# STM32H750 register map
File version: 2.7
CPU: CM7 r0p1, little endian, MPU, FPU, 4 interrupt priority bits
Registers are 32-bit, read-write, reset 0x0 unless marked. A register's access mark holds for its fields unless they carry their own. Offsets are from the block's base; [hi:lo] are bit positions; {n}, {i} and the like mark numbered series.

## COMP1
Base 0x58003800
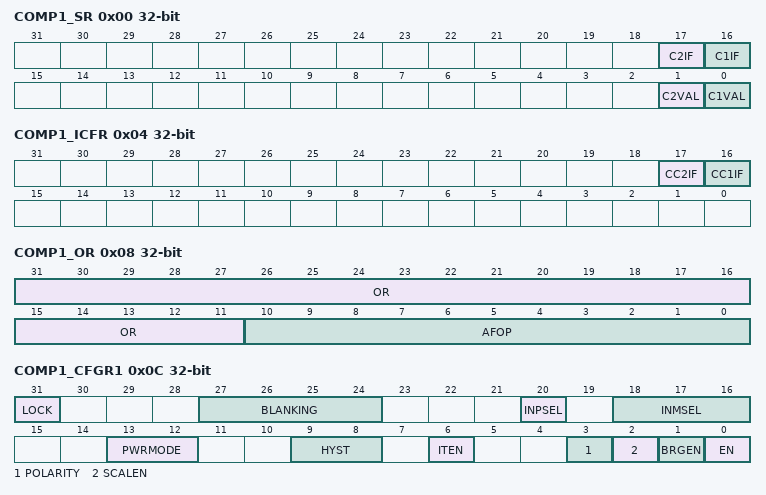
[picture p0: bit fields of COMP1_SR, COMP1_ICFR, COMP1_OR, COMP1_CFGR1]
0x00 COMP1_SR ro — Comparator status register
  [17] C2IF — COMP channel 2 Interrupt Flag
  [16] C1IF — COMP channel 1 Interrupt Flag
  [1] C2VAL — COMP channel 2 output status bit
  [0] C1VAL — COMP channel 1 output status bit
0x04 COMP1_ICFR wo — Comparator interrupt clear flag register
  [17] CC2IF — Clear COMP channel 2 Interrupt Flag
  [16] CC1IF — Clear COMP channel 1 Interrupt Flag
0x08 COMP1_OR — Comparator option register
  [31:11] OR — Option Register
  [10:0] AFOP — Selection of source for alternate function of output ports
0x0C COMP1_CFGR1 — Comparator configuration register 1
  [31] LOCK — Lock bit
  [27:24] BLANKING — COMP channel 1 blanking source selection bits
  [20] INPSEL — COMP channel 1 non-inverting input selection bit
  [18:16] INMSEL — COMP channel 1 inverting input selection field
  [13:12] PWRMODE — Power Mode of the COMP channel 1
  [9:8] HYST — COMP channel 1 hysteresis selection bits
  [6] ITEN — COMP channel 1 interrupt enable
  [3] POLARITY — COMP channel 1 polarity selection bit
  [2] SCALEN — Voltage scaler enable bit
  [1] BRGEN — Scaler bridge enable
  [0] EN — COMP channel 1 enable bit
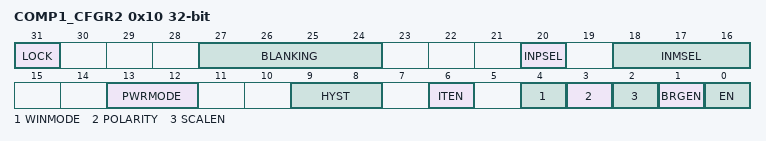
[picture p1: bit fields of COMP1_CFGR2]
0x10 COMP1_CFGR2 — Comparator configuration register 2
  [31] LOCK — Lock bit
  [27:24] BLANKING — COMP channel 1 blanking source selection bits
  [20] INPSEL — COMP channel 1 non-inverting input selection bit
  [18:16] INMSEL — COMP channel 1 inverting input selection field
  [13:12] PWRMODE — Power Mode of the COMP channel 1
  [9:8] HYST — COMP channel 1 hysteresis selection bits
  [6] ITEN — COMP channel 1 interrupt enable
  [4] WINMODE — Window comparator mode selection bit
  [3] POLARITY — COMP channel 1 polarity selection bit
  [2] SCALEN — Voltage scaler enable bit
  [1] BRGEN — Scaler bridge enable
  [0] EN — COMP channel 1 enable bit

## HSEM
Base 0x58026400
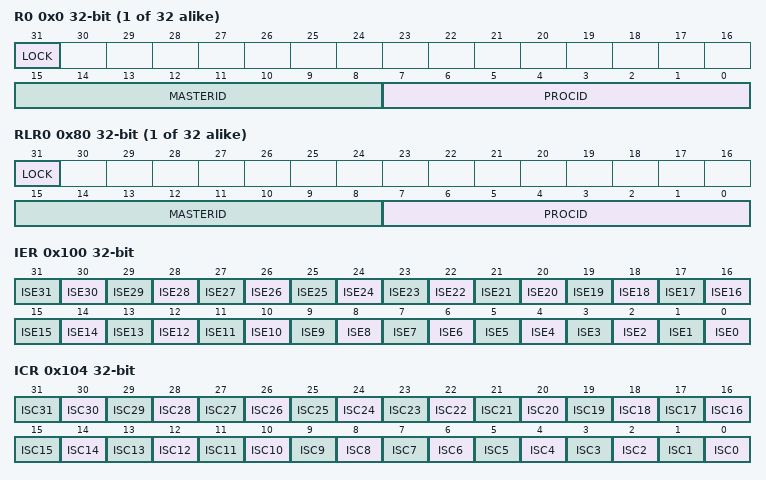
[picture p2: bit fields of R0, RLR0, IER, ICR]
{0x0+4i} R{i} (i=0..31) — HSEM register HSEM_R{i}
  [31] LOCK — Lock indication
    on read: 0=Free (Semaphore is free); 1=Locked (Semaphore is locked) | on write: 0=Free semaphore; 1=TryLock (Try to lock semaphore)
  [15:8] MASTERID range 0..15 — Semaphore MasterID
  [7:0] PROCID — Semaphore ProcessID
{0x80+4i} RLR{i} (i=0..31) ro — Semaphore {i} read lock register
  [31] LOCK — Lock indication
    0=Free (Semaphore is free); 1=Locked (Semaphore is locked)
  [15:8] MASTERID range 0..15 — Semaphore MasterID
  [7:0] PROCID — Semaphore ProcessID
0x100 IER — HSEM Interrupt enable register
  [n] ISE{n} (n=0..31) — Interrupt semaphore {n} enable bit
    0=Disabled (Interrupt generation disabled); 1=Enabled (Interrupt generation enabled)
0x104 ICR — HSEM Interrupt clear register
  [n] ISC{n} (n=0..31) — Interrupt semaphore {n} clear bit
    on read: 0=NoEffect (Always reads 0) | on write: 0=NoEffect (Interrupt semaphore x status ISFx and masked status MISFx not affected); 1=Clear (Interrupt semaphore x status ISFx and masked status MISFx cleared)
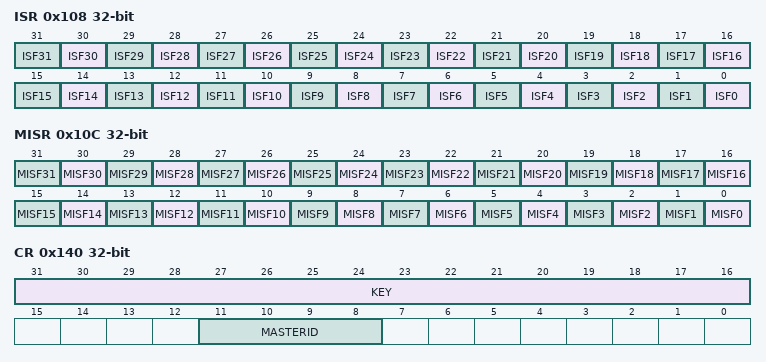
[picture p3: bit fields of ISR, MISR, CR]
0x108 ISR ro — HSEM Interrupt status register
  [n] ISF{n} (n=0..31) — Interrupt semaphore {n} status bit before enable (mask)
    0=NotPending (No interrupt pending); 1=Pending (Interrupt pending)
0x10C MISR ro — HSEM Masked interrupt status register
  [n] MISF{n} (n=0..31) — Masked interrupt semaphore {n} status bit after enable (mask)
    0=NotPending (No interrupt pending after masking); 1=Pending (Interrupt pending after masking)
0x140 CR — HSEM Clear register
  [31:16] KEY — Semaphore clear Key
  [11:8] MASTERID — MasterID of semaphores to be cleared
0x144 KEYR — HSEM Interrupt clear register
  [31:16] KEY — Semaphore Clear Key

## RNG
Base 0x48021800
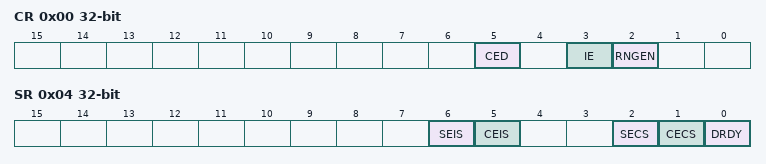
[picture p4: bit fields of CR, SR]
0x00 CR — RNG control register
  [5] CED — Clock error detection Note: The clock error detection can be used only when ck_rc48 or ck_pll1_q (ck_pll1_q = 48MHz) source is selected otherwise, CED bit must be equal to 1. The clock error detection cannot be enabled nor disabled on the fly when RNG peripheral is enabled, to enable or disable CED the RNG must be disabled.
    0=Enabled (Clock error detection is enabled); 1=Disabled (Clock error detection is disabled)
  [3] IE — Interrupt enable
    0=Disabled (RNG interrupt is disabled); 1=Enabled (RNG interrupt is enabled)
  [2] RNGEN — Random number generator enable
    0=Disabled (Random number generator is disabled); 1=Enabled (Random number generator is enabled)
0x04 SR access per field — RNG status register
  [6] SEIS rw write-0-clears — Seed error interrupt status This bit is set at the same time as SECS. It is cleared by writing it to 0. ** More than 64 consecutive bits at the same value (0 or 1) ** More than 32 consecutive alternances of 0 and 1 (0101010101...01) An interrupt is pending if IE = 1 in the RNG_CR register.
    on write: 0=Clear flag | on read: 0=No faulty sequence detected; 1=Fault (At least one faulty sequence has been detected. See **SECS** bit description for details. An interrupt is pending if IE = 1 in the RNG_CR register.)
  [5] CEIS rw write-0-clears — Clock error interrupt status This bit is set at the same time as CECS. It is cleared by writing it to 0. An interrupt is pending if IE = 1 in the RNG_CR register. Note: This bit is meaningless if CED (Clock error detection) bit in RNG_CR is equal to 1.
    on write: 0=Clear flag | on read: 0=Correct (The RNG clock is correct); 1=Slow (The RNG has been detected too slow An interrupt is pending if IE = 1 in the RNG_CR register)
  [2] SECS ro — Seed error current status ** More than 64 consecutive bits at the same value (0 or 1) ** More than 32 consecutive alternances of 0 and 1 (0101010101...01)
    0=No faulty sequence has currently been detected. If the SEIS bit is set, this means that a faulty sequence was detected and the situation has been recovered.; 1=Fault (At least one faulty sequence has been detected - see ref manual for details)
  [1] CECS ro — Clock error current status Note: This bit is meaningless if CED (Clock error detection) bit in RNG_CR is equal to 1.
    0=Correct (The RNG clock is correct. If the CEIS bit is set, this means that a slow clock was detected and the situation has been recovered.); 1=Slow (The RNG clock is too slow)
  [0] DRDY ro — Data ready Note: If IE=1 in RNG_CR, an interrupt is generated when DRDY=1. It can rise when the peripheral is disabled. When the output buffer becomes empty (after reading RNG_DR), this bit returns to 0 until a new random value is generated.
    0=Invalid (The RNG_DR register is not yet valid, no random data is available); 1=Valid (The RNG_DR register contains valid random data. Once the RNG_DR register has been read, this bit returns to 0 until a new random value is generated.)
0x08 DR ro — The RNG_DR register is a read-only register that delivers a 32-bit random value when read. The content of this register is valid when DRDY= 1, even if RNGEN=0.
  [31:0] RNDATA — Random data 32-bit random data which are valid when DRDY=1.
